# RN8XXX_V2 register map
File version: 1.0
Registers are 32-bit, read-write, reset 0x0 unless marked. A register's access mark holds for its fields unless they carry their own. Offsets are from the block's base; [hi:lo] are bit positions; {n}, {i} and the like mark numbered series; 'fields as' and 'values as' point back to an identical list.

## Timer0 — A 32-bit timer
Base 0x40010000
Same registers: Timer1 0x40014000
0x00 TC_CNT ro — current counting value
0x04 TC_PS — prescalor of counting clock
  [15:0] PS — prescalor.0 for no-prescaling,1 for 1/2 prescaling,2 for 1/3 prescaling,and so forth.
0x0C TC_DN — target counting value.0 for 1 prescaled clock cycle, 1 for 2 prescaled clock cycle, and so forth.
0x14 TC_CCD0 — capture(compare) channel No.0 data register
0x18 TC_CCD1 — campture(compare) channel No.1 data register
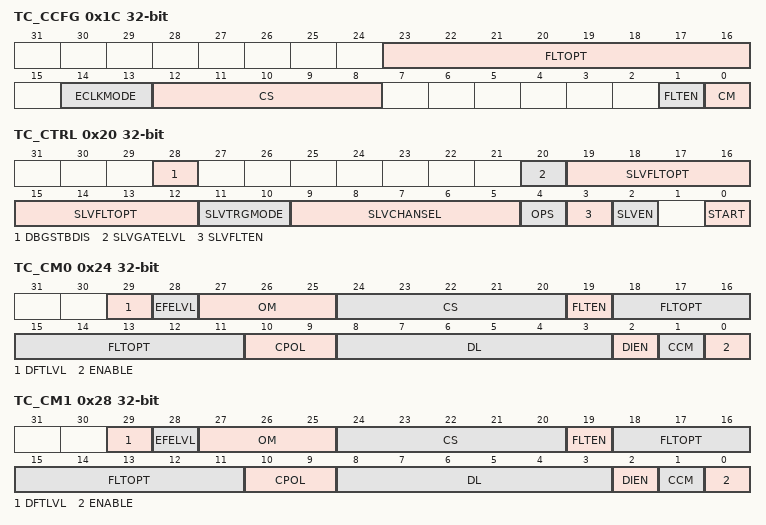
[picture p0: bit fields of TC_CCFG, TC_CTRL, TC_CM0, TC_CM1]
0x1C TC_CCFG — clock config register
  [23:16] FLTOPT — external clock source filter parameter
  [14:13] ECLKMODE — external clock mode
    0=rising_edge (every rising edge found on input recognized as a couting event); 1=falling_edge (every falling edge found on input recognized as a couting event); 2=both_edge (both rising and falling edge found on input recognized as a as a couting event)
  [12:8] CS — external clock souce selection
    {v}=uart{v}_rxd (selecting uart{v} rxd) (v=0..3); 4=tc_outn0 (negative output of channel 0 of TC1/TC0); 5=tc_outp0 (positive output of channel 0 of TC1/TC0); 6=tc_outn1 (negative output of channel 1 of TC1/TC0); 7=tc_outp1 (positive output of channel 1 of TC1/TC0); 8=uart4_rxd (selecting uart4 rxd); 9=uart5_rxd (selecting uart5 rxd); 10=iso7816_in0 (selecting iso7816 channel No.0 input(P41)); 11=iso7816_in1_dd (selecting iso7816 channel No.1 dual-direction input(P42)); 12=iso7816_in1_sd (selecting iso7816 channel No.1 single-direction input(P43)); 16=sf_out (selecting apparent power pulse output); 17=qf_out (selecting reactive power pulse output); 18=pf_out (selecting active power pulse output); 19=rtc_out (selecting rtc output); 20=p1_0 (selecting P10); 21=p1_1 (selecting P11); {v}=p1_{v-20} (selecting P{v-10}/P{v+30}) (v=22..27); 28=p3_0 (selecting P30); 29=p3_1 (selecting P31); 30=p3_3 (selecting P33); 31=p3_5 (selecting P35)
  [1] FLTEN — filter enable
    0=disable external clock source filtering; 1=enable external clock source filtering
  [0] CM — clock mode
    0=sys_clk (using on-chip system clock as input counting clock); 1=ext_clk (using external clock(to the timer) as input counting clock. refer to bitfield CS of register TC_CCFG for clock selection.)
0x20 TC_CTRL — control register
  [28] DBGSTBDIS — debugger halt standby disable
    0=disable (halt counting when SoC halted by debugger); 1=enable (keep counting when SoC halted by debugger)
  [20] SLVGATELVL — slave mode gating level control
    0=low (select low level sensitive gate); 1=high (select high level sensitive gate)
  [19:12] SLVFLTOPT — slave mode input filter produce
  [11:10] SLVTRGMODE — slave mode polarity control selection
    0=rising_edge (every rising edge found on input recognized as a trigger event); 1=falling_edge (every falling edge found on input recognized as a trigger event); 2=both_edge (both rising and falling edge found on input recognized as a as a trigger event); 3=gate_mode (level sensitive gate control)
  [9:5] SLVCHANSEL — slave mode input selection
    values as TC_CCFG.CS
  [4] OPS — one pulse mode selection
    0=disable (one pulse mode disabled(timer continue counting when overflow)); 1=enable (one pulse mode enabled(timer stop counting when overflow))
  [3] SLVFLTEN — slave mode input filter enable
    0=disabled; 1=enabled
  [2] SLVEN — slave mode enable
    0=disable (slave mode disabled(master mode enabled)); 1=enable (slave mode enabled)
  [0] START — timer start
    0=stoping timer; 1=start timer
0x24 TC_CM0 — capture(compare) channel No.0 mode register
  [29] DFTLVL — default level
    0=low (default level is low); 1=high (default level is high)
  [28] EFELVL — valid level
    0=low (valid level is low); 1=high (valid level is high)
  [27:25] OM — output mode
    0=no output generated; 1=set as valid level; 2=set as invalid level; 3=toggle output; 4=force_valid (force as valid level); 5=force_invalid (force as invalid level); 6=pwm1 (when tc_cnt less than tc_ccdx, set output as valid level); 7=pwm2 (when tc_cnt greater than tc_ccdx, set output as valid level)
  [24:20] CS — capture channel selection
    values as TC_CCFG.CS
  [19] FLTEN — filter enable
    0=disable (filter disabled); 1=enable (filter enabled)
  [18:11] FLTOPT — filter parameters
  [10:9] CPOL — capture polarity selection
    0=rising_edge (capture on rising edge); 1=falling_edge (capture on falling_edge edge); 2=both_edge (capture on both rising and falling edge); 3=reserved (Do not use)
  [8:3] DL — dead zone length
  [2] DIEN — dead zone insertion enable
    0=disable (dead zone insertion disabled); 1=enable (dead zone insertion enabled)
  [1] CCM — capture(compare) selection
    0=capture (using external event to capture internal counting value); 1=compare (using internal counting event to generate output)
  [0] ENABLE — channel enable
    0=disable (channel disabled); 1=enable (channel enabled)
0x28 TC_CM1 — capture(compare) channel No.1 mode register
  fields as TC_CM0
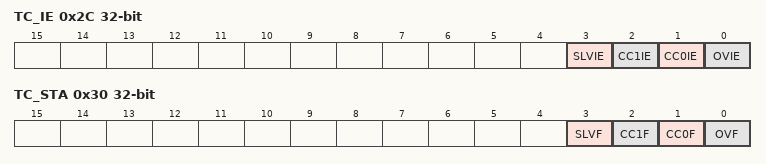
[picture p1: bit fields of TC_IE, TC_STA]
0x2C TC_IE — Interrupt enable register
  [3] SLVIE — slave interrupt enable
    0=disable (do not generate interrupt on slave event); 1=enable (generate interrupt on slave event)
  [2] CC1IE — compare(caputure) channel No.0 interrupt enable
    0=disable (do not generate interrupt on compare(capture) channel No.1 event); 1=enable (generate interrupt on compare(capture) channel No.1 event)
  [1] CC0IE — compare(caputure) channel No.0 interrupt enable
    0=disable (do not generate interrupt on compare(capture) channel No.0 event); 1=enable (generate interrupt on compare(capture) channel No.0 event)
  [0] OVIE — overflow interrupt enable
    0=disable (do not generate interrupt on overflow event); 1=enable (generate interrupt on overflow event)
0x30 TC_STA — status register
  [3] SLVF write-1-clears — slave status
    0=no_pending (no outstanding slave event found); 1=pending slave event found
  [2] CC1F write-1-clears — compare(capture) channel No.1 status
    0=no_pending (no outstanding compare(capture) channel No.1 event found); 1=pending compare(capture) channel No.1 event found
  [1] CC0F write-1-clears — compare(capture) channel No.0 status
    0=no_pending (no outstanding compare(capture) channel No.0 event found); 1=pending compare(capture) channel No.0 event found
  [0] OVF write-1-clears — overflow interrupt status
    0=no_pending (no outstanding overflow event found); 1=pending overflow event found
